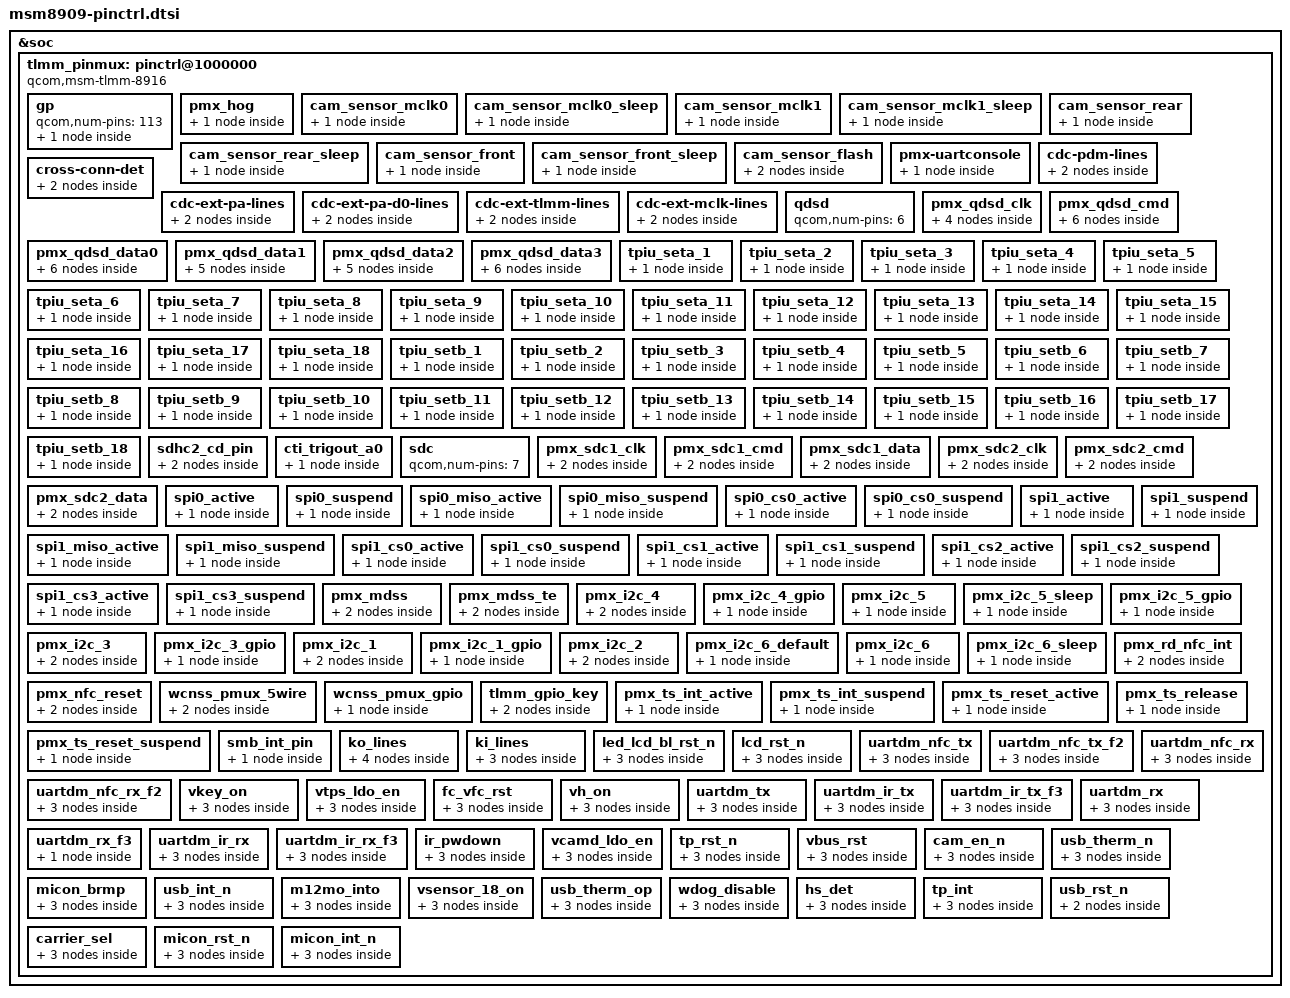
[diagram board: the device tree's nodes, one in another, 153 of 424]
/* Copyright (c) 2014-2015, The Linux Foundation. All rights reserved.
 *
 * This program is free software; you can redistribute it and/or modify
 * it under the terms of the GNU General Public License version 2 and
 * only version 2 as published by the Free Software Foundation.
 *
 * This program is distributed in the hope that it will be useful,
 * but WITHOUT ANY WARRANTY; without even the implied warranty of
 * MERCHANTABILITY or FITNESS FOR A PARTICULAR PURPOSE.  See the
 * GNU General Public License for more details.
 */
/*
 * This software is contributed or developed by KYOCERA Corporation.
 * (C) 2016 KYOCERA Corporation
 * (C) 2017 KYOCERA Corporation
 */

&soc {
	tlmm_pinmux: pinctrl@1000000 {
		compatible = "qcom,msm-tlmm-8916";
		reg = <0x1000000 0x300000>;
		interrupts = <0 208 0>;

		pinctrl-names = "default";
		pinctrl-0 = <&pmx_hog_default>;

		/*General purpose pins*/
		gp: gp {
			qcom,num-pins = <113>;
			#qcom,pin-cells = <1>;
			msm_gpio: msm_gpio {
				compatible = "qcom,msm-tlmm-gp";
				gpio-controller;
				#gpio-cells = <2>;
				interrupt-controller;
				#interrupt-cells = <2>;
				num_irqs = <113>;
			};
		};

		pmx_hog {
			qcom,pins = <&gp 1>, <&gp 9>, <&gp 10>, <&gp 11>,
					<&gp 24>, <&gp 31>, <&gp 32>, <&gp 68>,
					<&gp 69>, <&gp 71>, <&gp 72>, <&gp 73>,
					<&gp 74>, <&gp 75>, <&gp 77>, <&gp 78>,
					<&gp 79>, <&gp 80>,	<&gp 82>, <&gp 88>,
					<&gp 89>, <&gp 97>, <&gp 110>;
			qcom,num-grp-pins = <23>;
			qcom,pin-func = <0>;
			label = "hog";
			pmx_hog_default: pmx_hog_def {
				drive-strength = <2>;
				bias-pull-down;
				input-debounce = <0>;
			};
		};

		cam_sensor_mclk0 {
			/* MCLK */
			qcom,pins = <&gp 26>;
			qcom,num-grp-pins = <1>;
			qcom,pin-func = <1>;
			label = "cam-sensor-mclk0";
			 /* active state */
			cam_sensor_mclk0_default: default {
				drive-strength = <4>; /* 4 MA */
				output-low;
				bias-disable = <0>; /* No PULL */
			};
		};

		cam_sensor_mclk0_sleep {
			/* MCLK */
			qcom,pins = <&gp 26>;
			qcom,num-grp-pins = <1>;
			label = "cam-sensor-mclk0-sleep";
			/* suspend state */
			cam_sensor_mclk0_sleep: sleep {
				drive-strength = <4>; /* 4 MA */
				output-low;
				bias-disable = <0>; /* No PULL */
			};
		};

		cam_sensor_mclk1 {
			/* MCLK */
			qcom,pins = <&gp 27>;
			qcom,num-grp-pins = <1>;
			qcom,pin-func = <1>;
			label = "cam-sensor-mclk1";
			/* active state */
			cam_sensor_mclk1_default: default {
				drive-strength = <2>; /* 2 MA */
				bias-disable = <0>; /* No PULL */
			};
		};

		cam_sensor_mclk1_sleep {
			/* MCLK */
			qcom,pins = <&gp 27>;
			qcom,num-grp-pins = <1>;
			label = "cam-sensor-mclk1-sleep";
			/* suspend state */
			cam_sensor_mclk1_sleep: sleep {
				drive-strength = <2>; /* 2 MA */
				bias-pull-down; /* PULL DOWN */
			};
		};

		cam_sensor_rear {
			/* RESET */
			qcom,pins =  <&gp 35>;
			qcom,num-grp-pins = <1>;
			qcom,pin-func = <0>;
			label = "cam-sensor-rear";
			/* active state */
			cam_sensor_rear_default: default {
				drive-strength = <2>; /* 2 MA */
				output-low;
				bias-disable = <0>; /* No PULL */
			};
		};

		cam_sensor_rear_sleep {
			/* RESET */
			qcom,pins =  <&gp 35>;
			qcom,num-grp-pins = <1>;
			qcom,pin-func = <0>;
			label = "cam-sensor-rear-sleep";
			/*suspended state */
			cam_sensor_rear_sleep: sleep {
				drive-strength = <2>; /* 2 MA */
				output-low;
				bias-disable = <0>; /* No PULL */
			};
		};

		cam_sensor_front {
			/* RESET, STANDBY */
			qcom,pins = <&gp 28>, <&gp 33>;
			qcom,num-grp-pins = <2>;
			qcom,pin-func = <0>;
			label = "cam_sensor_front";
			/* active state */
			cam_sensor_front_default: default {
				drive-strength = <2>; /* 2 MA */
				bias-disable = <0>; /* No PULL */
			};
		};

		cam_sensor_front_sleep {
			/* RESET, STANDBY */
			qcom,pins = <&gp 28>, <&gp 33>;
			qcom,num-grp-pins = <2>;
			qcom,pin-func = <0>;
			label = "cam-sensor-front-sleep";
			/*suspended state */\
			cam_sensor_front_sleep: sleep {
				drive-strength = <2>; /* 2 MA */
				bias-pull-down = <0>; /* PULL DOWN */
			};
		};

		cam_sensor_flash {
			/* FLASH_RESET,FLASH_EN,FLASH_NOW */
			qcom,pins = <&gp 36>, <&gp 31>,<&gp 32> ;
			qcom,num-grp-pins = <3>;
			qcom,pin-func = <0>;
			label = "cam_sensor_flash";
			/* active state */
			cam_sensor_flash_default: default {
				drive-strength = <2>; /* 2 MA */
				bias-disable = <0>; /* No PULL */
			};
			/*suspended state */
			cam_sensor_flash_sleep: sleep {
				drive-strength = <2>; /* 2 MA */
				bias-pull-down = <0>; /* PULL DOWN */
			};
		};

		pmx-uartconsole {
			qcom,pins = <&gp 4>, <&gp 5>;
			qcom,num-grp-pins = <2>;
			qcom,pin-func = <2>;
			label = "uart-console";
			uart_console_sleep: uart-console {
				drive-strength = <2>;
				bias-pull-down;
			};
		};

		cdc-pdm-lines {
			qcom,pins = <&gp 59>, <&gp 60>, <&gp 61>,
					<&gp 62>, <&gp 63>, <&gp 64>;
			qcom,num-grp-pins = <6>;
			qcom,pin-func = <1>;
			label = "cdc-pdm-lines";
			cdc_pdm_lines_act: pdm_lines_on {
				drive-strength = <8>;
			};
			cdc_pdm_lines_sus: pdm_lines_off {
				drive-strength = <2>;
				bias-pull-down;
			};
		};

		cross-conn-det {
			qcom,pins = <&gp 97>;
			qcom,num-grp-pins = <1>;
			qcom,pin-func = <0>;
			label = "cross-conn-det-sw";
			cross_conn_det_act: lines_on {
				drive-strength = <8>;
				output-low;
				bias-pull-down;
			};
			cross_conn_det_sus: lines_off {
				drive-strength = <2>;
				bias-disable;
			};
		};

//		vdd_spkdrv {
//			qcom,pins = <&gp 4>;
//			qcom,num-grp-pins = <1>;
//			qcom,pin-func = <0>;
//			label = "vdd_spkdrv";
//			vdd_spkdrv_act: vdd_spkdrv_on {
//				drive-strength = <8>;
//				bias-pull-up;
//			};
//			vdd_spkdrv_sus: vdd_spkdrv_off {
//				drive-strength = <2>;
//				bias-disable;
//			};
//		};

		cdc-ext-pa-lines {
			qcom,pins = <&gp 94>, <&gp 96>,
					 <&gp 110>;
			qcom,num-grp-pins = <3>;
			qcom,pin-func = <1>;
			label = "cdc-ext-pa-lines";
			cdc_ext_pa_act: ext_pa_on {
				drive-strength = <8>;
			};
			cdc_ext_pa_sus: ext_pa_off {
				drive-strength = <2>;
				bias-disable;
			};
		};

		cdc-ext-pa-d0-lines {
			qcom,pins = <&gp 95>;
			qcom,num-grp-pins = <1>;
			qcom,pin-func = <2>;
			label = "cdc-ext-pa-d0-lines";
			cdc_ext_pa_d0_act: ext_pa_d0_on {
				drive-strength = <8>;
			};
			cdc_ext_pa_d0_sus: ext_pa_d0_off {
				drive-strength = <2>;
				bias-disable;
			};
		};

		cdc-ext-tlmm-lines {
			qcom,pins = <&gp 0>, <&gp 1>, <&gp 2>,
					 <&gp 3>;
			qcom,num-grp-pins = <4>;
			qcom,pin-func = <2>;
			label = "cdc-ext-tlmm-lines";
			cdc_ext_tlmm_act: ext_tlmm_on {
				drive-strength = <8>;
			};
			cdc_ext_tlmm_sus: ext_tlmm_off {
				drive-strength = <2>;
				bias-disable;
			};
		};

		cdc-ext-mclk-lines {
			qcom,pins = <&gp 98>;
			qcom,num-grp-pins = <1>;
			qcom,pin-func = <2>;
			label = "cdc-ext-mclk-lines";
			cdc_ext_mclk_act: ext_mclk_on {
				drive-strength = <8>;
			};
			cdc_ext_mclk_sus: ext_mclk_off {
				drive-strength = <2>;
				bias-disable;
			};
		};

		/* QDSD pin type */
		qdsd: qdsd {
			/* 0-> clk, 1 -> cmd, 2->data0, 3->data1, 4->data2, 5->data3 */
			qcom,num-pins = <6>;

			#qcom,pin-cells = <1>;
		};

		pmx_qdsd_clk {
			qcom,pins = <&qdsd 0>;
			qcom,num-grp-pins = <1>;
			label = "qdsd-clk";
			qdsd_clk_sdcard: clk_sdcard {
				bias-disable; /* NO pull */
				drive-strength = <7>; /* 7 MA */
			};
			qdsd_clk_trace: clk_trace {
				bias-pull-down; /* pull down */
				drive-strength = <0>; /* 0 MA */
			};
			qdsd_clk_swdtrc: clk_swdtrc {
				bias-pull-down; /* pull down */
				drive-strength = <0>; /* 0 MA */
			};
			qdsd_clk_spmi: clk_spmi {
				bias-pull-down; /* pull down */
				drive-strength = <0>; /* 0 MA */
			};
		};

		pmx_qdsd_cmd {
			qcom,pins = <&qdsd 1>;
			qcom,num-grp-pins = <1>;
			label = "qdsd-cmd";
			qdsd_cmd_sdcard: cmd_sdcard {
				bias-pull-down; /* pull down */
				drive-strength = <3>; /* 3 MA */
			};
			qdsd_cmd_trace: cmd_trace {
				bias-pull-down; /* pull down */
				drive-strength = <0>; /* 0 MA */
			};
			qdsd_cmd_swduart: cmd_uart {
				bias-pull-up; /* pull up */
				drive-strength = <0>; /* 0 MA */
			};
			qdsd_cmd_swdtrc: cmd_swdtrc {
				bias-pull-up; /* pull up */
				drive-strength = <0>; /* 0 MA */
			};
			qdsd_cmd_jtag: cmd_jtag {
				bias-disable; /* NO pull */
				drive-strength = <3>; /* 3 MA */
			};
			qdsd_cmd_spmi: cmd_spmi {
				bias-pull-down; /* pull down */
				drive-strength = <4>; /* 4 MA */
			};
		};

		pmx_qdsd_data0 {
			qcom,pins = <&qdsd 2>;
			qcom,num-grp-pins = <1>;
			label = "qdsd-data0";
			qdsd_data0_sdcard: data0_sdcard {
				bias-pull-down; /* pull down */
				drive-strength = <3>; /* 3 MA */
			};
			qdsd_data0_trace: data0_trace {
				bias-pull-down; /* pull down */
				drive-strength = <3>; /* 3 MA */
			};
			qdsd_data0_swduart: data0_uart {
				bias-pull-down; /* pull down */
				drive-strength = <0>; /* 0 MA */
			};
			qdsd_data0_swdtrc: data0_swdtrc {
				bias-pull-down; /* pull down */
				drive-strength = <0>; /* 0 MA */
			};
			qdsd_data0_jtag: data0_jtag {
				bias-pull-up; /* pull up */
				drive-strength = <0>; /* 0 MA */
			};
			qdsd_data0_spmi: data0_spmi {
				bias-pull-down; /* pull down */
				drive-strength = <0>; /* 0 MA */
			};
		};

		pmx_qdsd_data1 {
			qcom,pins = <&qdsd 3>;
			qcom,num-grp-pins = <1>;
			label = "qdsd-data1";
			qdsd_data1_sdcard: data1_sdcard {
				bias-pull-down; /* pull down */
				drive-strength = <3>; /* 3 MA */
			};
			qdsd_data1_trace: data1_trace {
				bias-pull-down; /* pull down */
				drive-strength = <3>; /* 3 MA */
			};
			qdsd_data1_swduart: data1_uart {
				bias-pull-down; /* pull down */
				drive-strength = <0>; /* 0 MA */
			};
			qdsd_data1_swdtrc: data1_swdtrc {
				bias-pull-down; /* pull down */
				drive-strength = <0>; /* 0 MA */
			};
			qdsd_data1_jtag: data1_jtag {
				bias-pull-down; /* pull down */
				drive-strength = <0>; /* 0 MA */
			};
		};

		pmx_qdsd_data2 {
			qcom,pins = <&qdsd 4>;
			qcom,num-grp-pins = <1>;
			label = "qdsd-data2";
			qdsd_data2_sdcard: data2_sdcard {
				bias-pull-down; /* pull down */
				drive-strength = <3>; /* 3 MA */
			};
			qdsd_data2_trace: data2_trace {
				bias-pull-down; /* pull down */
				drive-strength = <3>; /* 3 MA */
			};
			qdsd_data2_swduart: data2_uart {
				bias-pull-down; /* pull down */
				drive-strength = <0>; /* 0 MA */
			};
			qdsd_data2_swdtrc: data2_swdtrc {
				bias-pull-down; /* pull down */
				drive-strength = <0>; /* 0 MA */
			};
			qdsd_data2_jtag: data2_jtag {
				bias-pull-up; /* pull up */
				drive-strength = <3>; /* 3 MA */
			};
		};

		pmx_qdsd_data3 {
			qcom,pins = <&qdsd 5>;
			qcom,num-grp-pins = <1>;
			label = "qdsd-data3";
			qdsd_data3_sdcard: data3_sdcard {
				bias-pull-down; /* pull down */
				drive-strength = <3>; /* 3 MA */
			};
			qdsd_data3_trace: data3_trace {
				bias-pull-down; /* pull down */
				drive-strength = <3>; /* 3 MA */
			};
			qdsd_data3_swduart: data3_uart {
				bias-pull-up; /* pull up */
				drive-strength = <0>; /* 0 MA */
			};
			qdsd_data3_swdtrc: data3_swdtrc {
				bias-pull-up; /* pull up */
				drive-strength = <0>; /* 0 MA */
			};
			qdsd_data3_jtag: data3_jtag {
				bias-pull-up; /* pull up */
				drive-strength = <0>; /* 0 MA */
			};
			qdsd_data3_spmi: data3_spmi {
				bias-pull-down; /* pull down */
				drive-strength = <3>; /* 3 MA */
			};
		};

		/* CoreSight */
		tpiu_seta_1 {
			qcom,pins = <&gp 6>;
			qcom,num-grp-pins = <1>;
			qcom,pin-func = <11>;
			label = "tpiu-seta-1";
			seta_1: seta {
				drive-strength = <16>;
				bias-disable;
			};
		};


		tpiu_seta_2 {
			qcom,pins = <&gp 8>;
			qcom,num-grp-pins = <1>;
			qcom,pin-func = <8>;
			label = "tpiu-seta-2";
			seta_2: seta {
				drive-strength = <16>;
				bias-disable;
			};
		};

		tpiu_seta_3 {
			qcom,pins = <&gp 9>;
			qcom,num-grp-pins = <1>;
			qcom,pin-func = <7>;
			label = "tpiu-seta-3";
			seta_3: seta {
				drive-strength = <16>;
				bias-disable;
			};
		};

		tpiu_seta_4 {
			qcom,pins = <&gp 10>;
			qcom,num-grp-pins = <1>;
			qcom,pin-func = <4>;
			label = "tpiu-seta-4";
			seta_4: seta {
				drive-strength = <16>;
				bias-disable;
			};
		};

		tpiu_seta_5 {
			qcom,pins = <&gp 39>;
			qcom,num-grp-pins = <1>;
			qcom,pin-func = <2>;
			label = "tpiu-seta-5";
			seta_5: seta {
				drive-strength = <16>;
				bias-disable;
			};
		};

		tpiu_seta_6 {
			qcom,pins = <&gp 40>;
			qcom,num-grp-pins = <1>;
			qcom,pin-func = <2>;
			label = "tpiu-seta-6";
			seta_6: seta {
				drive-strength = <16>;
				bias-disable;
			};
		};

		tpiu_seta_7 {
			qcom,pins = <&gp 41>;
			qcom,num-grp-pins = <1>;
			qcom,pin-func = <2>;
			label = "tpiu-seta-7";
			seta_7: seta {
				drive-strength = <16>;
				bias-disable;
			};
		};

		tpiu_seta_8 {
			qcom,pins = <&gp 42>;
			qcom,num-grp-pins = <1>;
			qcom,pin-func = <2>;
			label = "tpiu-seta-8";
			seta_8: seta {
				drive-strength = <16>;
				bias-disable;
			};
		};

		tpiu_seta_9 {
			qcom,pins = <&gp 43>;
			qcom,num-grp-pins = <1>;
			qcom,pin-func = <3>;
			label = "tpiu-seta-9";
			seta_9: seta {
				drive-strength = <16>;
				bias-disable;
			};
		};

		tpiu_seta_10 {
			qcom,pins = <&gp 45>;
			qcom,num-grp-pins = <1>;
			qcom,pin-func = <3>;
			label = "tpiu-seta-10";
			seta_10: seta {
				drive-strength = <16>;
				bias-disable;
			};
		};

		tpiu_seta_11 {
			qcom,pins = <&gp 46>;
			qcom,num-grp-pins = <1>;
			qcom,pin-func = <2>;
			label = "tpiu-seta-11";
			seta_11: seta {
				drive-strength = <16>;
				bias-disable;
			};
		};

		tpiu_seta_12 {
			qcom,pins = <&gp 47>;
			qcom,num-grp-pins = <1>;
			qcom,pin-func = <2>;
			label = "tpiu-seta-12";
			seta_12: seta {
				drive-strength = <16>;
				bias-disable;
			};
		};

		tpiu_seta_13 {
			qcom,pins = <&gp 48>;
			qcom,num-grp-pins = <1>;
			qcom,pin-func = <2>;
			label = "tpiu-seta-13";
			seta_13: seta {
				drive-strength = <16>;
				bias-disable;
			};
		};

		tpiu_seta_14 {
			qcom,pins = <&gp 58>;
			qcom,num-grp-pins = <1>;
			qcom,pin-func = <1>;
			label = "tpiu-seta-14";
			seta_14: seta {
				drive-strength = <16>;
				bias-disable;
			};
		};

		tpiu_seta_15 {
			qcom,pins = <&gp 65>;
			qcom,num-grp-pins = <1>;
			qcom,pin-func = <3>;
			label = "tpiu-seta-15";
			seta_15: seta {
				drive-strength = <16>;
				bias-disable;
			};
		};

		tpiu_seta_16 {
			qcom,pins = <&gp 94>;
			qcom,num-grp-pins = <1>;
			qcom,pin-func = <3>;
			label = "tpiu-seta-16";
			seta_16: seta {
				drive-strength = <16>;
				bias-disable;
			};
		};

		tpiu_seta_17 {
			qcom,pins = <&gp 96>;
			qcom,num-grp-pins = <1>;
			qcom,pin-func = <4>;
			label = "tpiu-seta-17";
			seta_17: seta {
				drive-strength = <16>;
				bias-disable;
			};
		};

		tpiu_seta_18 {
			qcom,pins = <&gp 97>;
			qcom,num-grp-pins = <1>;
			qcom,pin-func = <2>;
			label = "tpiu-seta-18";
			seta_18: seta {
				drive-strength = <16>;
				bias-disable;
			};
		};

		tpiu_setb_1 {
			qcom,pins = <&gp 4>;
			qcom,num-grp-pins = <1>;
			qcom,pin-func = <13>;
			label = "tpiu-setb-1";
			setb_1: setb {
				drive-strength = <16>;
				bias-disable;
			};
		};

		tpiu_setb_2 {
			qcom,pins = <&gp 5>;
			qcom,num-grp-pins = <1>;
			qcom,pin-func = <13>;
			label = "tpiu-setb-2";
			setb_2: setb {
				drive-strength = <16>;
				bias-disable;
			};
		};

		tpiu_setb_3 {
			qcom,pins = <&gp 14>;
			qcom,num-grp-pins = <1>;
			qcom,pin-func = <9>;
			label = "tpiu-setb-3";
			setb_3: setb {
				drive-strength = <16>;
				bias-disable;
			};
		};

		tpiu_setb_4 {
			qcom,pins = <&gp 16>;
			qcom,num-grp-pins = <1>;
			qcom,pin-func = <7>;
			label = "tpiu-setb-4";
			setb_4: setb {
				drive-strength = <16>;
				bias-disable;
			};
		};

		tpiu_setb_5 {
			qcom,pins = <&gp 17>;
			qcom,num-grp-pins = <1>;
			qcom,pin-func = <8>;
			label = "tpiu-setb-5";
			setb_5: setb {
				drive-strength = <16>;
				bias-disable;
			};
		};

		tpiu_setb_6 {
			qcom,pins = <&gp 26>;
			qcom,num-grp-pins = <1>;
			qcom,pin-func = <10>;
			label = "tpiu-setb-6";
			setb_6: setb {
				drive-strength = <16>;
				bias-disable;
			};
		};

		tpiu_setb_7 {
			qcom,pins = <&gp 27>;
			qcom,num-grp-pins = <1>;
			qcom,pin-func = <10>;
			label = "tpiu-setb-7";
			setb_7: setb {
				drive-strength = <16>;
				bias-disable;
			};
		};

		tpiu_setb_8 {
			qcom,pins = <&gp 28>;
			qcom,num-grp-pins = <1>;
			qcom,pin-func = <10>;
			label = "tpiu-setb-8";
			setb_8: setb {
				drive-strength = <16>;
				bias-disable;
			};
		};

		tpiu_setb_9 {
			qcom,pins = <&gp 29>;
			qcom,num-grp-pins = <1>;
			qcom,pin-func = <7>;
			label = "tpiu-setb-9";
			setb_9: setb {
				drive-strength = <16>;
				bias-disable;
			};
		};

		tpiu_setb_10 {
			qcom,pins = <&gp 30>;
			qcom,num-grp-pins = <1>;
			qcom,pin-func = <7>;
			label = "tpiu-setb-10";
			setb_10: setb {
				drive-strength = <16>;
				bias-disable;
			};
		};

		tpiu_setb_11 {
			qcom,pins = <&gp 31>;
			qcom,num-grp-pins = <1>;
			qcom,pin-func = <8>;
			label = "tpiu-setb-11";
			setb_11: setb {
				drive-strength = <16>;
				bias-disable;
			};
		};

		tpiu_setb_12 {
			qcom,pins = <&gp 32>;
			qcom,num-grp-pins = <1>;
			qcom,pin-func = <3>;
			label = "tpiu-setb-12";
			setb_12: setb {
				drive-strength = <16>;
				bias-disable;
			};
		};

		tpiu_setb_13 {
			qcom,pins = <&gp 33>;
			qcom,num-grp-pins = <1>;
			qcom,pin-func = <2>;
			label = "tpiu-setb-13";
			setb_13: setb {
				drive-strength = <16>;
				bias-disable;
			};
		};

		tpiu_setb_14 {
			qcom,pins = <&gp 34>;
			qcom,num-grp-pins = <1>;
			qcom,pin-func = <2>;
			label = "tpiu-setb-14";
			setb_14: setb {
				drive-strength = <16>;
				bias-disable;
			};
		};

		tpiu_setb_15 {
			qcom,pins = <&gp 35>;
			qcom,num-grp-pins = <1>;
			qcom,pin-func = <2>;
			label = "tpiu-setb-15";
			setb_15: setb {
				drive-strength = <16>;
				bias-disable;
			};
		};

		tpiu_setb_16 {
			qcom,pins = <&gp 36>;
			qcom,num-grp-pins = <1>;
			qcom,pin-func = <1>;
			label = "tpiu-setb-16";
			setb_16: setb {
				drive-strength = <16>;
				bias-disable;
			};
		};

		tpiu_setb_17 {
			qcom,pins = <&gp 37>;
			qcom,num-grp-pins = <1>;
			qcom,pin-func = <2>;
			label = "tpiu-setb-17";
			setb_17: setb {
				drive-strength = <16>;
				bias-disable;
			};
		};

		tpiu_setb_18 {
			qcom,pins = <&gp 93>;
			qcom,num-grp-pins = <1>;
			qcom,pin-func = <1>;
			label = "tpiu-setb-18";
			setb_18: setb {
				drive-strength = <16>;
				bias-disable;
			};
		};

		sdhc2_cd_pin {
			qcom,pins = <&gp 38>;
			qcom,num-grp-pins = <1>;
			qcom,pin-func = <0>;
			label = "cd-gpio";
			sdc2_cd_on: cd_on {
				drive-strength = <2>;
				bias-pull-up;
			};
			sdc2_cd_off: cd_off {
				drive-strength = <2>;
				bias-disable;
			};
		};

		cti_trigout_a0 {
			qcom,pins = <&gp 23>;
			qcom,num-grp-pins = <1>;
			qcom,pin-func = <2>;
			label = "cti-trigout-a0";
			trigout_a0: trigout_a0 {
				drive-strength = <2>;
				bias-disable;
			};
		};

		/* SDC pin type */
		sdc: sdc {
			/* 0-2 for sdc1 4-6 for sdc2 */
			qcom,num-pins = <7>;
			/* Order of pins */
			/* SDC1: CLK -> 0, CMD -> 1, DATA -> 2 */
			/* SDC2: CLK -> 4, CMD -> 5, DATA -> 6 */
			#qcom,pin-cells = <1>;
		};

		pmx_sdc1_clk {
			qcom,pins = <&sdc 0>;
			qcom,num-grp-pins = <1>;
			label = "sdc1-clk";
			sdc1_clk_on: clk_on {
				bias-disable; /* NO pull */
				drive-strength = <16>; /* 16 MA */
			};
			sdc1_clk_off: clk_off {
				bias-disable; /* NO pull */
				drive-strength = <2>; /* 2 MA */
			};
		};

		pmx_sdc1_cmd {
			qcom,pins = <&sdc 1>;
			qcom,num-grp-pins = <1>;
			label = "sdc1-cmd";
			sdc1_cmd_on: cmd_on {
				bias-disable; /* NO pull */
				drive-strength = <8>; /* 8 MA */
			};
			sdc1_cmd_off: cmd_off {
				bias-pull-up; /* pull up */
				drive-strength = <2>; /* 2 MA */
			};
		};

		pmx_sdc1_data {
			qcom,pins = <&sdc 2>;
			qcom,num-grp-pins = <1>;
			label = "sdc1-data";
			sdc1_data_on: data_on {
				bias-pull-up; /* pull up */
				drive-strength = <8>; /* 8 MA */
			};
			sdc1_data_off: data_off {
				bias-pull-up; /* pull up */
				drive-strength = <2>; /* 2 MA */
			};
		};

		pmx_sdc2_clk {
			qcom,pins = <&sdc 4>;
			qcom,num-grp-pins = <1>;
			label = "sdc2-clk";
			sdc2_clk_on: clk_on {
				bias-disable; /* NO pull */
				drive-strength = <12>; /* 12 MA */
			};
			sdc2_clk_off: clk_off {
				bias-pull-down; /* pull down */
				drive-strength = <2>; /* 2 MA */
			};
		};

		pmx_sdc2_cmd {
			qcom,pins = <&sdc 5>;
			qcom,num-grp-pins = <1>;
			label = "sdc2-cmd";
			sdc2_cmd_on: cmd_on {
				bias-pull-up; /* pull up */
				drive-strength = <8>; /* 8 MA */
			};
			sdc2_cmd_off: cmd_off {
				bias-pull-down; /* pull down */
				drive-strength = <2>; /* 2 MA */
			};
		};

		pmx_sdc2_data {
			qcom,pins = <&sdc 6>;
			qcom,num-grp-pins = <1>;
			label = "sdc2-data";
			sdc2_data_on: data_on {
				bias-pull-up; /* pull up */
				drive-strength = <8>; /* 8 MA */
			};
			sdc2_data_off: data_off {
				bias-pull-down; /* pull down */
				drive-strength = <2>; /* 2 MA */
			};
		};
		spi0_active {
                        /* MOSI, CLK */
                        qcom,pins = <&gp 8>, <&gp 11>;
                        qcom,num-grp-pins = <2>;
                        qcom,pin-func = <1>;
                        label = "spi0-active";
                        /* active state */
                        spi0_default: spi0_default {
                                drive-strength = <2>; /* 2 MA */
                                output-low;
                                bias-disable = <0>;
                        };
                };

                spi0_suspend {
                        /* MOSI, CLK */
                        qcom,pins = <&gp 8>, <&gp 11>;
                        qcom,num-grp-pins = <2>;
                        qcom,pin-func = <0>;
                        label = "spi0-suspend";
                        /* suspended state */
                        spi0_sleep: spi0_sleep {
                                drive-strength = <2>; /* 2 MA */
                                output-low;
                                bias-disable = <0>;
                        };
                };

		spi0_miso_active {
                        /* MISO */
                        qcom,pins = <&gp 9>;
                        qcom,num-grp-pins = <1>;
                        qcom,pin-func = <1>;
                        label = "spi0-miso-active";
                        /* active state */
                        spi0_miso_default: spi0_miso_default {
                                drive-strength = <2>; /* 2 MA */
				input-debounce = <0>;
                                bias-pull-down;
                        };
                };
                spi0_miso_suspend {
                        /* MISO */
                        qcom,pins = <&gp 9>;
                        qcom,num-grp-pins = <1>;
                        qcom,pin-func = <0>;
                        label = "spi0-miso-suspend";
                        /* suspended state */
                        spi0_miso_sleep: spi0_miso_sleep {
                                drive-strength = <2>; /* 2 MA */
				input-debounce = <0>;
                                bias-pull-down;
                        };
                };

                spi0_cs0_active {
                        /* CS */
                        qcom,pins = <&gp 10>;
                        qcom,num-grp-pins = <1>;
                        qcom,pin-func = <1>;
                        label = "spi0-cs0-active";
                        spi0_cs0_active: cs0_active {
                                drive-strength = <2>;
                                bias-disable = <0>;
                        };
                };


                spi0_cs0_suspend {
                        /* CS */
                        qcom,pins = <&gp 10>;
                        qcom,num-grp-pins = <1>;
                        qcom,pin-func = <0>;
                        label = "spi0-cs0-suspend";
                        spi0_cs0_sleep: cs0_sleep {
                                drive-strength = <2>;
                                output-high;
                                bias-disable = <0>;
                        };
                };

		spi1_active {
                        /* MOSI, CLK */
                        qcom,pins = <&gp 4>, <&gp 7>;
                        qcom,num-grp-pins = <2>;
                        qcom,pin-func = <1>;
                        label = "spi1-active";
                        /* active state */
                        spi1_default: spi1_default {
                                drive-strength = <4>; /* 4 MA */
                                bias-disable = <0>;
                        };
                };

                spi1_suspend {
                        /* MOSI, CLK */
                        qcom,pins = <&gp 4>, <&gp 7>;
                        qcom,num-grp-pins = <2>;
                        qcom,pin-func = <0>;
                        label = "spi1-suspend";
                        /* suspended state */
                        spi1_sleep: spi1_sleep {
                                drive-strength = <4>; /* 4 MA */
                                output-low;
                                bias-disable = <0>;
                        };
                };

		spi1_miso_active {
                        /* MISO */
                        qcom,pins = <&gp 5>;
                        qcom,num-grp-pins = <1>;
                        qcom,pin-func = <1>;
                        label = "spi1-miso-active";
                        /* active state */
                        spi1_miso_default: spi1_miso_default {
                                drive-strength = <2>; /* 2 MA */
                                input-debounce = <0>;
                                bias-disable = <0>;
                        };
                };
                spi1_miso_suspend {
                        /* MISO */
                        qcom,pins = <&gp 5>;
                        qcom,num-grp-pins = <1>;
                        qcom,pin-func = <0>;
                        label = "spi1-miso-suspend";
                        /* suspended state */
                        spi1_miso_sleep: spi1_miso_sleep {
                                drive-strength = <2>; /* 2 MA */
                                input-debounce = <0>;
                                bias-pull-down;
                        };
                };

                spi1_cs0_active {
                        /* CS */
                        qcom,pins = <&gp 6>;
                        qcom,num-grp-pins = <1>;
                        qcom,pin-func = <1>;
                        label = "spi1-cs0-active";
                        spi1_cs0_active: cs0_active {
                                drive-strength = <2>;
                                bias-disable = <0>;
                        };
                };


                spi1_cs0_suspend {
                        /* CS */
                        qcom,pins = <&gp 6>;
                        qcom,num-grp-pins = <1>;
                        qcom,pin-func = <0>;
                        label = "spi1-cs0-suspend";
                        spi1_cs0_sleep: cs0_sleep {
                                drive-strength = <2>;
                                output-low;
                                bias-disable = <0>;
                        };
                };

                spi1_cs1_active {
                        /* CS */
                        qcom,pins = <&gp 97>;
                        qcom,num-grp-pins = <1>;
                        qcom,pin-func = <1>;
                        label = "spi1-cs1-active";
                        spi1_cs1_active: cs1_active {
                                drive-strength = <2>;
                                bias-disable = <0>;
                        };
                };


                spi1_cs1_suspend {
                        /* CS */
                        qcom,pins = <&gp 97>;
                        qcom,num-grp-pins = <1>;
                        qcom,pin-func = <0>;
                        label = "spi1-cs1-suspend";
                        spi1_cs1_sleep: cs1_sleep {
                                drive-strength = <2>;
                                output-low;
                                bias-disable = <0>;
                        };
                };

                spi1_cs2_active {
                        /* CS */
                        qcom,pins = <&gp 37>;
                        qcom,num-grp-pins = <1>;
                        qcom,pin-func = <1>;
                        label = "spi1-cs2-active";
                        spi1_cs2_active: cs2_active {
                                drive-strength = <4>;
                                bias-disable = <0>;
                        };
                };


                spi1_cs2_suspend {
                        /* CS */
                        qcom,pins = <&gp 37>;
                        qcom,num-grp-pins = <1>;
                        qcom,pin-func = <0>;
                        label = "spi1-cs2-suspend";
                        spi1_cs2_sleep: cs2_sleep {
                                drive-strength = <4>;
                                output-high;
                                bias-disable = <0>;
                        };
                };

                spi1_cs3_active {
                        /* CS */
                        qcom,pins = <&gp 65>;
                        qcom,num-grp-pins = <1>;
                        qcom,pin-func = <2>;
                        label = "spi1-cs3-active";
                        spi1_cs3_active: cs3_active {
                                drive-strength = <2>;
                                bias-disable = <0>;
                        };
                };


                spi1_cs3_suspend {
                        /* CS */
                        qcom,pins = <&gp 65>;
                        qcom,num-grp-pins = <1>;
                        qcom,pin-func = <0>;
                        label = "spi1-cs3-suspend";
                        spi1_cs3_sleep: cs3_sleep {
                                drive-strength = <2>;
                                output-low;
                                bias-disable = <0>;
                        };
                };

		pmx_mdss: pmx_mdss {
			label = "mdss-pins";
			qcom,pin-func = <0>;

			mdss_dsi_active: active {
				drive-strength = <8>; /* 8 mA */
				bias-disable = <0>; /* no pull */
				output-high;
			};
			mdss_dsi_suspend: suspend {
				drive-strength = <2>; /* 2 mA */
				bias-pull-down; /* pull down */
				output-low;
			};
		};

		pmx_mdss_te: pmx_mdss_te {
			label = "mdss-te-pin";
			qcom,pin-func = <1>;
			mdss_te_active: active {
				drive-strength = <2>; /* 2 mA */
				bias-pull-down; /* pull down */
				input-debounce = <0>;
			};
			mdss_te_suspend: suspend {
				drive-strength = <2>; /* 2 mA */
				bias-pull-down; /* pull down */
				input-debounce = <0>;
			};
		};

		pmx_i2c_4 {
			qcom,pins = <&gp 14>, <&gp 15>; /* SDA, SCL */
			qcom,num-grp-pins = <2>;
			qcom,pin-func = <2>;
			label = "pmx_i2c_4";

			i2c_4_active: i2c_4_active {
				drive-strength = <2>;
				bias-disable;
			};

			i2c_4_sleep: i2c_4_sleep {
				drive-strength = <2>;
				bias-disable;
			};
		};

		pmx_i2c_4_gpio {
			/* CLK, DATA */
			qcom,pins = <&gp 14>, <&gp 15>;
			qcom,num-grp-pins = <2>;
			qcom,pin-func = <0>;
			label = "pmx_i2c_4_gpio";

			i2c_4_gpio: i2c_4_gpio {
				drive-strength = <2>; /* 2 MA */
				bias-disable;         /* No PULL */
				input-debounce = <0>;
			};
		};

		pmx_i2c_5 {
                        /* CLK, DATA */
                        qcom,pins = <&gp 19>, <&gp 18>;
                        qcom,num-grp-pins = <2>;
                        qcom,pin-func = <2>;
                        label = "pmx_i2c_5";

                        i2c_5_active: i2c_5_active {
                                drive-strength = <2>; /* 2 MA */
                                bias-disable = <0>; /* No PULL */
                        };
                };

		pmx_i2c_5_sleep {
                        /* CLK, DATA */
                        qcom,pins = <&gp 19>, <&gp 18>;
                        qcom,num-grp-pins = <2>;
                        qcom,pin-func = <2>;
                        label = "pmx_i2c_5_sleep";

                        i2c_5_sleep: i2c_5_sleep {
                                drive-strength = <2>; /* 2 MA */
                                bias-disable = <0>; /* No PULL */
                        };
                };

		pmx_i2c_5_gpio {
			/* CLK, DATA */
			qcom,pins = <&gp 19>, <&gp 18>;
			qcom,num-grp-pins = <2>;
			qcom,pin-func = <0>;
			label = "pmx_i2c_5_gpio";

			i2c_5_gpio: i2c_5_gpio {
				drive-strength = <2>; /* 2 MA */
				bias-disable;         /* No PULL */
				input-debounce = <0>;
			};
		};

		pmx_i2c_3 {
                        /* CLK, DATA */
			qcom,pins = <&gp 29>, <&gp 30>;
			qcom,num-grp-pins = <2>;
			qcom,pin-func = <1>;
			label = "pmx_i2c_3";

			i2c_3_active: i2c_3_active {
				drive-strength = <2>; /* 2 MA */
				bias-disable = <0>; /* No PULL */
			};

			i2c_3_sleep: i2c_3_sleep {
				drive-strength = <2>; /* 2 MA */
				bias-disable = <0>; /* No PULL */
			};
		};

		pmx_i2c_3_gpio {
			/* CLK, DATA */
			qcom,pins = <&gp 29>, <&gp 30>;
			qcom,num-grp-pins = <2>;
			qcom,pin-func = <0>;
			label = "pmx_i2c_3_gpio";

			i2c_3_gpio: i2c_3_gpio {
				drive-strength = <2>; /* 2 MA */
				bias-disable;         /* No PULL */
				input-debounce = <0>;
			};
		};

		pmx_i2c_1 {
                        /* CLK, DATA */
			qcom,pins = <&gp 6>, <&gp 7>;
			qcom,num-grp-pins = <2>;
			qcom,pin-func = <3>;
			label = "pmx_i2c_1";

			i2c_1_active: i2c_1_active {
				drive-strength = <2>; /* 2 MA */
				bias-disable = <0>; /* No PULL */
			};

			i2c_1_sleep: i2c_1_sleep {
				drive-strength = <2>; /* 2 MA */
				bias-disable = <0>; /* No PULL */
			};
		};

		pmx_i2c_1_gpio {
			/* CLK, DATA */
			qcom,pins = <&gp 6>, <&gp 7>;
			qcom,num-grp-pins = <2>;
			qcom,pin-func = <0>;
			label = "pmx_i2c_1_gpio";

			i2c_1_gpio: i2c_1_gpio {
				drive-strength = <2>; /* 2 MA */
				bias-disable;         /* No PULL */
				input-debounce = <0>;
			};
		};

		pmx_i2c_2 {
			/* CLK, DATA */
			qcom,pins = <&gp 111>, <&gp 112>;
			qcom,num-grp-pins = <2>;
			qcom,pin-func = <3>;
			label = "pmx_i2c_2";
			/* active state */
			i2c_2_active: i2c_2_active{
				drive-strength = <2>; /* 2 MA */
				bias-disable; /* No PULL */
			};
			/* suspended state */
				i2c_2_sleep: i2c_2_sleep {
				drive-strength = <2>; /* 2 MA */
				bias-disable; /* No PULL */
			};
		};

		pmx_i2c_6_default {
			/* CLK, DATA */
			qcom,pins = <&gp 10>, <&gp 11>;
			qcom,num-grp-pins = <2>;
			qcom,pin-func = <0>;
			label = "pmx_i2c_6_default";
				i2c_6_default: i2c_6_default {
				drive-strength = <2>; /* 2 MA */
				bias-pull-down;
			};
		};

		pmx_i2c_6 {
			/* CLK, DATA */
			qcom,pins = <&gp 10>, <&gp 11>;
			qcom,num-grp-pins = <2>;
			qcom,pin-func = <2>;
			label = "pmx_i2c_6";
			/* active state */
			i2c_6_active: i2c_6_active{
				drive-strength = <2>; /* 2 MA */
				bias-disable; /* No PULL */
			};
		};

		pmx_i2c_6_sleep {
			/* CLK, DATA */
			qcom,pins = <&gp 10>, <&gp 11>;
			qcom,num-grp-pins = <2>;
			qcom,pin-func = <0>;
			label = "pmx_i2c_6_sleep";
			/* suspended state */
				i2c_6_sleep: i2c_6_sleep {
				drive-strength = <2>; /* 2 MA */
				bias-pull-down;
			};
		};

		pmx_rd_nfc_int{
			qcom,pins = <&gp 21>;
			qcom,pin-func = <0>;
			qcom,num-grp-pins = <1>;
			label = "pmx_nfc_int";

			nfc_int_active: active {
				drive-strength = <6>;
				bias-pull-up;
			};

			nfc_int_suspend: suspend {
				drive-strength = <6>;
				bias-pull-up;
			};
		};

		pmx_nfc_reset{
			qcom,pins = <&gp 20>;
			qcom,pin-func = <0>;
			qcom,num-grp-pins = <1>;
			label = "pmx_nfc_disable";

			nfc_disable_active: active {
				drive-strength = <6>;
				bias-pull-up;
			};

			nfc_disable_suspend: suspend {
				drive-strength = <6>;
				bias-disable;
			};
		};

		wcnss_pmux_5wire: wcnss_pmux_5wire {
			/* Uses general purpose pins */
			qcom,pins = <&gp 40>, <&gp 41>,
				    <&gp 42>, <&gp 43>,
				    <&gp 44>;
			qcom,num-grp-pins = <5>;
			qcom,pin-func = <1>;
			label = "wcnss_5wire_pins";
			/* Active configuration of bus pins */
			wcnss_default: wcnss_default {
			        drive-strength = <6>; /* 6 MA */
			        bias-pull-up; /* PULL UP */
			};
			wcnss_sleep: wcnss_sleep {
			        drive-strength = <2>; /* 2 MA */
			        bias-pull-down; /* PULL Down */
			};
		};

		wcnss_pmux_gpio: wcnss_pmux_gpio {
			/* Uses general purpose pins */
			qcom,pins = <&gp 40>, <&gp 41>,
				    <&gp 42>, <&gp 43>,
				    <&gp 44>;
			qcom,num-grp-pins = <5>;
			qcom,pin-func = <0>;
			label = "wcnss_5gpio_pins";
			/* Active configuration of bus pins */
			wcnss_gpio_default: wcnss_gpio_default {
			        drive-strength = <6>; /* 6 MA */
			        bias-pull-up; /* PULL UP */
			};
		};

		tlmm_gpio_key {
			qcom,pins = <&gp 25>;
			qcom,pin-func = <0>;
			qcom,num-grp-pins = <1>;
			label = "tlmm_gpio_key";
			gpio_key_active: gpio_key_active {
				drive-strength = <2>;
				input-debounce = <0>;
				bias-pull-up;
			};
			gpio_key_suspend: gpio_key_suspend {
				drive-strength = <2>;
				input-debounce = <0>;
				bias-pull-up;
			};
		};

		/* add pingrp for touchscreen */
		pmx_ts_int_active {
			qcom,pins = <&gp 50>;
			qcom,pin-func = <0>;
			qcom,num-grp-pins = <1>;
			label = "pmx_ts_int_active";

			ts_int_active: ts_int_active {
				drive-strength = <2>;
				bias-pull-down;
			};
		};

		pmx_ts_int_suspend {
			qcom,pins = <&gp 50>;
			qcom,pin-func = <0>;
			qcom,num-grp-pins = <1>;
			label = "pmx_ts_int_suspend";

			ts_int_suspend: ts_int_suspend {
				drive-strength = <2>;
				bias-pull-down;
			};
		};

		pmx_ts_reset_active {
			qcom,pins = <&gp 65>;
			qcom,pin-func = <0>;
			qcom,num-grp-pins = <1>;
			label = "pmx_ts_reset_active";

			ts_reset_active: ts_reset_active {
				drive-strength = <2>;
				bias-disable;
			};
		};

		pmx_ts_reset_suspend {
			qcom,pins = <&gp 65>;
			qcom,pin-func = <0>;
			qcom,num-grp-pins = <1>;
			label = "pmx_ts_reset_suspend";

			ts_reset_suspend: ts_reset_suspend {
				drive-strength = <2>;
				bias-disable;
			};
		};

		pmx_ts_release {
			qcom,pins = <&gp 50>, <&gp 65>;
			qcom,num-grp-pins = <2>;
			label = "pmx_ts_release";

			ts_release: ts_release {
				drive-strength = <2>;
				bias-pull-down;
			};
		};

		smb_int_pin {
			qcom,pins = <&gp 58>;
			qcom,num-grp-pins = <1>;
			qcom,pin-func = <0>;
			label = "smb1360_int_gpio";
			smb_int_default: smb_int_default {
				drive-strength = <2>;	/* 2 MA */
				input-debounce = <0>;
				bias-disable;
			};
		};

		ko_lines {
			qcom,pins = <&gp 3>, <&gp 16>, <&gp 17>, <&gp 28>,
					<&gp 33>, <&gp 34>, <&gp 50>, <&gp 57>,
					<&gp 65>, <&gp 92>;
			qcom,pin-func = <0>;
			qcom,num-grp-pins = <10>;
			label = "ko";
			ko_default: ko_default {
				drive-strength = <2>;
				output-low;
				bias-disable;
			};
			ko_active: ko_active {
				drive-strength = <2>;
				output-low;
				bias-disable;
			};
			ko_suspend: ko_suspend {
				drive-strength = <2>;
				output-low;
				bias-pull-down;
			};
			ko_prescan: ko_prescan {
				drive-strength = <2>;
                input-enable;
				bias-pull-up;
			};
		};
		ki_lines {
			qcom,pins = <&gp 90>, <&gp 91>, <&gp 94>,
					<&gp 95>, <&gp 96>, <&gp 98>;
			qcom,pin-func = <0>;
			qcom,num-grp-pins = <6>;
			label = "ki";
			ki_default: ki_default {
				drive-strength = <2>;
				input-debounce = <0>;
				bias-pull-up;
			};
			ki_active: ki_active {
				drive-strength = <2>;
				input-debounce = <0>;
				bias-pull-up;
			};
			ki_suspend: ki_suspend {
				drive-strength = <2>;
				input-debounce = <0>;
				bias-pull-up;
			};
		};

		led_lcd_bl_rst_n {
			qcom,pins = <&gp 0>;
			qcom,pin-func = <0>;
			qcom,num-grp-pins = <1>;
			label = "led_lcd_bl_rst_n";
			led_lcd_bl_rst_n_default: led_lcd_bl_rst_n_default {
				drive-strength = <2>;
				output-low;
				bias-disable;
			};
			led_lcd_bl_rst_n_active: led_lcd_bl_rst_n_active {
				drive-strength = <2>;
				output-low;
				bias-disable;
			};
			led_lcd_bl_rst_n_suspend: led_lcd_bl_rst_n_suspend {
				drive-strength = <2>;
				output-high;
				bias-disable;
			};
		};

		lcd_rst_n {
			qcom,pins = <&gp 2>;
			qcom,pin-func = <0>;
			qcom,num-grp-pins = <1>;
			label = "lcd_rst_n";
			lcd_rst_n_default: lcd_rst_n_default {
				drive-strength = <2>;
				output-low;
				bias-disable;
			};
			lcd_rst_n_active: lcd_rst_n_active {
				drive-strength = <2>;
				output-low;
				bias-disable;
			};
			lcd_rst_n_suspend: lcd_rst_n_suspend {
				drive-strength = <2>;
				output-low;
				bias-disable;
			};
		};

		uartdm_nfc_tx {
			qcom,pins = <&gp 4>;
			qcom,pin-func = <0>;
			qcom,num-grp-pins = <1>;
			label = "uartdm_nfc_tx";
			uartdm_nfc_tx_default: uartdm_nfc_tx_default {
				drive-strength = <2>;
				output-high;
				bias-pull-up;
			};
			uartdm_nfc_tx_active: uartdm_nfc_tx_active {
				drive-strength = <2>;
				output-high;
				bias-pull-up;
			};
			uartdm_nfc_tx_suspend: uartdm_nfc_tx_suspend {
				drive-strength = <2>;
				output-high;
				bias-pull-up;
			};
		};

		uartdm_nfc_tx_f2 {
			qcom,pins = <&gp 4>;
			qcom,pin-func  = <2>;
			qcom,num-grp-pins = <1>;
			label = "uartdm_nfc_tx_f2";
			uartdm_nfc_tx_f2_default: uartdm_nfc_tx_f2_default {
				drive-strength = <2>;
				output-high;
				bias-pull-up;
			};
			uartdm_nfc_tx_f2_active: uartdm_nfc_tx_f2_active {
				drive-strength = <2>;
				output-high;
				bias-pull-up;
			};
			uartdm_nfc_tx_f2_suspend: uartdm_nfc_tx_f2_suspend {
				drive-strength = <2>;
				output-high;
				bias-pull-up;
			};
		};

		uartdm_nfc_rx {
			qcom,pins = <&gp 5>;
			qcom,pin-func = <0>;
			qcom,num-grp-pins = <1>;
			label = "uartdm_nfc_rx";
			uartdm_nfc_rx_default: uartdm_nfc_rx_default {
				drive-strength = <2>;
				input-debounce = <0>;
				bias-pull-up;
			};
			uartdm_nfc_rx_active: uartdm_nfc_rx_active {
				drive-strength = <2>;
				input-debounce = <0>;
				bias-pull-up;
			};
			uartdm_nfc_rx_suspend: uartdm_nfc_rx_suspend {
				drive-strength = <2>;
				input-debounce = <0>;
				bias-pull-up;
			};
		};

		uartdm_nfc_rx_f2 {
			qcom,pins = <&gp 5>;
			qcom,pin-func  = <2>;
			qcom,num-grp-pins = <1>;
			label = "uartdm_nfc_rx_f2";
			uartdm_nfc_rx_f2_default: uartdm_nfc_rx_f2_default {
				drive-strength = <2>;
				input-debounce = <0>;
				bias-pull-up;
			};
			uartdm_nfc_rx_f2_active: uartdm_nfc_rx_f2_active {
				drive-strength = <2>;
				input-debounce = <0>;
				bias-pull-up;
			};
			uartdm_nfc_rx_f2_suspend: uartdm_nfc_rx_f2_suspend {
				drive-strength = <2>;
				input-debounce = <0>;
				bias-pull-up;
			};
		};

		vkey_on {
			qcom,pins = <&gp 8>;
			qcom,pin-func = <0>;
			qcom,num-grp-pins = <1>;
			label = "vkey_on";
			vkey_on_default: vkey_on_default {
				drive-strength = <2>;
				output-low;
				bias-disable;
			};
			vkey_on_active: vkey_on_active {
				drive-strength = <2>;
				output-low;
				bias-disable;
			};
			vkey_on_suspend: vkey_on_suspend {
				drive-strength = <2>;
				output-low;
				bias-disable;
			};
		};

		vtps_ldo_en {
			qcom,pins = <&gp 9>;
			qcom,pin-func = <0>;
			qcom,num-grp-pins = <1>;
			label = "vtps_ldo_en";
			vtps_ldo_en_default: vtps_ldo_en_default {
				drive-strength = <2>;
				output-high;
				bias-disable;
			};
			vtps_ldo_en_active: vtps_ldo_en_active {
				drive-strength = <2>;
				output-high;
				bias-disable;
			};
			vtps_ldo_en_suspend: vtps_ldo_en_suspend {
				drive-strength = <2>;
				output-low;
				bias-disable;
			};
		};

		fc_vfc_rst {
			qcom,pins = <&gp 12>;
			qcom,pin-func = <0>;
			qcom,num-grp-pins = <1>;
			label = "fc_vfc_rst";
			fc_vfc_rst_default: fc_vfc_rst_default {
				drive-strength = <4>;
				output-low;
				bias-disable;
			};
			fc_vfc_rst_active: fc_vfc_rst_active {
				drive-strength = <4>;
				output-low;
				bias-disable;
			};
			fc_vfc_rst_suspend: fc_vfc_rst_suspend {
				drive-strength = <4>;
				output-low;
				bias-disable;
			};
		};

		vh_on {
			qcom,pins = <&gp 13>;
			qcom,pin-func = <0>;
			qcom,num-grp-pins = <1>;
			label = "vh_on";
			vh_on_default: vh_on_default {
				drive-strength = <2>;
				output-low;
				bias-disable;
			};
			vh_on_active: vh_on_active {
				drive-strength = <2>;
				output-low;
				bias-disable;
			};
			vh_on_suspend: vh_on_suspend {
				drive-strength = <2>;
				output-low;
				bias-disable;
			};
		};

		uartdm_tx {
			qcom,pins = <&gp 20>;
			qcom,pin-func = <0>;
			qcom,num-grp-pins = <1>;
			label = "uartdm_tx";
			uartdm_tx_default: uartdm_tx_default {
				drive-strength = <2>;
				output-low;
				bias-disable;
			};
			uartdm_tx_active: uartdm_tx_active {
				drive-strength = <2>;
				output-low;
				bias-disable;
			};
			uartdm_tx_suspend: uartdm_tx_suspend {
				drive-strength = <2>;
				output-low;
				bias-pull-down;
			};
		};

		uartdm_ir_tx {
			qcom,pins = <&gp 20>;
			qcom,pin-func = <0>;
			qcom,num-grp-pins = <1>;
			label = "uartdm_ir_tx";
			uartdm_ir_tx_default: uartdm_ir_tx_default {
				drive-strength = <2>;
				output-low;
				bias-disable;
			};
			uartdm_ir_tx_active: uartdm_ir_tx_active {
				drive-strength = <2>;
				output-low;
				bias-disable;
			};
			uartdm_ir_tx_suspend: uartdm_ir_tx_suspend {
				drive-strength = <2>;
				output-low;
				bias-pull-down;
			};
		};

		uartdm_ir_tx_f3 {
			qcom,pins = <&gp 20>;
			qcom,pin-func = <3>;
			qcom,num-grp-pins = <1>;
			label = "uartdm_ir_tx_f3";
			uartdm_ir_tx_f3_default: uartdm_ir_tx_f3_default {
				drive-strength = <2>;
				output-low;
				bias-disable;
			};
			uartdm_ir_tx_f3_active: uartdm_ir_tx_f3_active {
				drive-strength = <2>;
				output-low;
				bias-disable;
			};
			uartdm_ir_tx_f3_suspend: uartdm_ir_tx_f3_suspend {
				drive-strength = <2>;
				output-low;
				bias-pull-down;
			};
		};

		uartdm_rx {
			qcom,pins = <&gp 21>;
			qcom,pin-func = <0>;
			qcom,num-grp-pins = <1>;
			label = "uartdm_rx";
			uartdm_rx_default: uartdm_rx_default {
				drive-strength = <2>;
				input-debounce = <0>;
				bias-disable;
			};
			uartdm_rx_active: uartdm_rx_active {
				drive-strength = <2>;
				input-debounce = <0>;
				bias-disable;
			};
			uartdm_rx_suspend: uartdm_rx_suspend {
				drive-strength = <2>;
				input-debounce = <0>;
				bias-disable;
			};
		};

		uartdm_rx_f3 {
			qcom,pins = <&gp 21>;
			qcom,pin-func = <3>;
			qcom,num-grp-pins = <1>;
			label = "uartdm_rx_f3";
			uartdm_rx_f3_active: uartdm_rx_f3_active {
				drive-strength = <2>;
				input-debounce = <0>;
				bias-disable;
			};
		};

		uartdm_ir_rx {
			qcom,pins = <&gp 21>;
			qcom,pin-func = <0>;
			qcom,num-grp-pins = <1>;
			label = "uartdm_ir_rx";
			uartdm_ir_rx_default: uartdm_ir_rx_default {
				drive-strength = <2>;
				input-debounce = <0>;
				bias-disable;
			};
			uartdm_ir_rx_active: uartdm_ir_rx_active {
				drive-strength = <2>;
				input-debounce = <0>;
				bias-disable;
			};
			uartdm_ir_rx_suspend: uartdm_ir_rx_suspend {
				drive-strength = <2>;
				input-debounce = <0>;
				bias-disable;
			};
		};

		uartdm_ir_rx_f3 {
			qcom,pins = <&gp 21>;
			qcom,pin-func = <3>;
			qcom,num-grp-pins = <1>;
			label = "uartdm_ir_rx_f3";
			uartdm_ir_rx_f3_default: uartdm_ir_rx_f3_default {
				drive-strength = <2>;
				input-debounce = <0>;
				bias-disable;
			};
			uartdm_ir_rx_f3_active: uartdm_ir_rx_f3_active {
				drive-strength = <2>;
				input-debounce = <0>;
				bias-disable;
			};
			uartdm_ir_rx_f3_suspend: uartdm_ir_rx_f3_suspend {
				drive-strength = <2>;
				input-debounce = <0>;
				bias-disable;
			};
		};

		ir_pwdown {
			qcom,pins = <&gp 22>;
			qcom,pin-func = <0>;
			qcom,num-grp-pins = <1>;
			label = "ir_pwdown";
			ir_pwdown_default: ir_pwdown_default {
				drive-strength = <2>;
				output-high;
				bias-disable;
			};
			ir_pwdown_active: ir_pwdown_active {
				drive-strength = <2>;
				output-high;
				bias-disable;
			};
			ir_pwdown_suspend: ir_pwdown_suspend {
				drive-strength = <2>;
				output-high;
				bias-pull-up;
			};
		};

		vcamd_ldo_en {
			qcom,pins = <&gp 23>;
			qcom,pin-func = <0>;
			qcom,num-grp-pins = <1>;
			label = "vcamd_ldo_en";
			vcamd_ldo_en_default: vcamd_ldo_en_default {
				drive-strength = <2>;
				output-low;
				bias-disable;
			};
			vcamd_ldo_en_active: vcamd_ldo_en_active {
				drive-strength = <2>;
				output-low;
				bias-disable;
			};
			vcamd_ldo_en_suspend: vcamd_ldo_en_suspend {
				drive-strength = <2>;
				output-low;
				bias-pull-down;
			};
		};

		tp_rst_n {
			qcom,pins = <&gp 24>;
			qcom,pin-func = <0>;
			qcom,num-grp-pins = <1>;
			label = "tp_rst_n";
			tp_rst_n_default: tp_rst_n_default {
				drive-strength = <2>;
				output-low;
				bias-disable;
			};
			tp_rst_n_active: tp_rst_n_active {
				drive-strength = <2>;
				output-low;
				bias-disable;
			};
			tp_rst_n_suspend: tp_rst_n_suspend {
				drive-strength = <2>;
				output-low;
				bias-disable;
			};
		};

		vbus_rst {
			qcom,pins = <&gp 27>;
			qcom,pin-func = <0>;
			qcom,num-grp-pins = <1>;
			label = "vbus_rst";
			vbus_rst_default: vbus_rst_default {
				drive-strength = <2>;
				output-low;
				bias-disable;
			};
			vbus_rst_active: vbus_rst_active {
				drive-strength = <2>;
				output-low;
				bias-disable;
			};
			vbus_rst_suspend: vbus_rst_suspend {
				drive-strength = <2>;
				output-low;
				bias-disable;
			};
		};

		cam_en_n {
			qcom,pins = <&gp 31>;
			qcom,pin-func = <0>;
			qcom,num-grp-pins = <1>;
			label = "cam_en_n";
			cam_en_n_default: cam_en_n_default {
				drive-strength = <2>;
				input-debounce = <0>;
				bias-pull-down;
			};
			cam_en_n_active: cam_en_n_active {
				drive-strength = <2>;
				input-debounce = <0>;
				bias-pull-down;
			};
			cam_en_n_suspend: cam_en_n_suspend {
				drive-strength = <2>;
				input-debounce = <0>;
				bias-pull-down;
			};
		};

		usb_therm_n {
			qcom,pins = <&gp 36>;
			qcom,pin-func = <0>;
			qcom,num-grp-pins = <1>;
			label = "usb_therm_n";
			usb_therm_n_default: usb_therm_n_default {
				drive-strength = <2>;
				input-debounce = <0>;
				bias-pull-up;
			};
			usb_therm_n_active: usb_therm_n_active {
				drive-strength = <2>;
				input-debounce = <0>;
				bias-pull-up;
			};
			usb_therm_n_suspend: usb_therm_n_suspend {
				drive-strength = <2>;
				input-debounce = <0>;
				bias-pull-up;
			};
		};

		micon_brmp {
			qcom,pins = <&gp 38>;
			qcom,pin-func = <0>;
			qcom,num-grp-pins = <1>;
			label = "micon_brmp";
			micon_brmp_default: micon_brmp_default {
				drive-strength = <4>;
				input-debounce = <0>;
				bias-pull-down;
			};
			micon_brmp_active: micon_brmp_active {
				drive-strength = <4>;
				output-low = <0>;
				bias-disable;
			};
			micon_brmp_suspend: micon_brmp_suspend {
				drive-strength = <4>;
				input-debounce = <0>;
				bias-pull-down;
			};
		};

		usb_int_n {
			qcom,pins = <&gp 49>;
			qcom,pin-func = <0>;
			qcom,num-grp-pins = <1>;
			label = "usb_int_n";
			usb_int_n_default: usb_int_n_default {
				drive-strength = <2>;
				input-debounce = <0>;
				bias-pull-up;
			};
			usb_int_n_active: usb_int_n_active {
				drive-strength = <2>;
				input-debounce = <0>;
				bias-pull-up;
			};
			usb_int_n_suspend: usb_int_n_suspend {
				drive-strength = <2>;
				input-debounce = <0>;
				bias-pull-up;
			};
		};

		m12mo_into {
			qcom,pins = <&gp 50>;
			qcom,pin-func = <0>;
			qcom,num-grp-pins = <1>;
			label = "m12mo_into";
			m12mo_into_default: m12mo_into_default {
				drive-strength = <2>;
				input-debounce = <0>;
				bias-pull-down;
			};
			m12mo_into_active: m12mo_into_active {
				drive-strength = <2>;
				input-debounce = <0>;
				bias-pull-down;
			};
			m12mo_into_suspend: m12mo_into_suspend {
				drive-strength = <2>;
				input-debounce = <0>;
				bias-pull-down;
			};
		};

		vsensor_18_on {
			qcom,pins = <&gp 51>;
			qcom,pin-func = <0>;
			qcom,num-grp-pins = <1>;
			label = "vsensor_18_on";
			vsensor_18_on_default: vsensor_18_on_default {
				drive-strength = <2>;
				output-low;
				bias-disable;
			};
			vsensor_18_on_active: vsensor_18_on_active {
				drive-strength = <2>;
				output-high;
				bias-disable;
			};
			vsensor_18_on_suspend: vsensor_18_on_suspend {
				drive-strength = <2>;
				output-high;
				bias-pull-up;
			};
		};

		usb_therm_op {
			qcom,pins = <&gp 52>;
			qcom,pin-func = <0>;
			qcom,num-grp-pins = <1>;
			label = "usb_therm_op";
			usb_therm_op_default: usb_therm_op_default {
				drive-strength = <2>;
				input-debounce = <0>;
				bias-pull-down;
			};
			usb_therm_op_active: usb_therm_op_active {
				drive-strength = <2>;
				input-debounce = <0>;
				bias-pull-down;
			};
			usb_therm_op_suspend: usb_therm_op_suspend {
				drive-strength = <2>;
				input-debounce = <0>;
				bias-pull-down;
			};
		};

		wdog_disable {
			qcom,pins = <&gp 76>;
			qcom,pin-func = <0>;
			qcom,num-grp-pins = <1>;
			label = "wdog_disable";
			wdog_disable_default: wdog_disable_default {
				drive-strength = <2>;
				input-debounce = <0>;
				bias-pull-down;
			};
			wdog_disable_active: wdog_disable_active {
				drive-strength = <2>;
				input-debounce = <0>;
				bias-pull-down;
			};
			wdog_disable_suspend: wdog_disable_suspend {
				drive-strength = <2>;
				input-debounce = <0>;
				bias-pull-down;
			};
		};

		hs_det {
			qcom,pins = <&gp 93>;
			qcom,pin-func = <0>;
			qcom,num-grp-pins = <1>;
			label = "hs_det";
			hs_det_default: hs_det_default {
				drive-strength = <2>;
				output-high;
				bias-disable;
			};
			hs_det_active: hs_det_active {
				drive-strength = <2>;
				output-high;
				bias-disable;
			};
			hs_det_suspend: hs_det_suspend {
				drive-strength = <2>;
				output-high;
				bias-disable;
			};
		};

		tp_int {
			qcom,pins = <&gp 97>;
			qcom,pin-func = <0>;
			qcom,num-grp-pins = <1>;
			label = "tp_int";
			tp_int_default: tp_int_default {
				drive-strength = <2>;
				input-debounce = <0>;
				bias-pull-down;
			};
			tp_int_active: tp_int_active {
				drive-strength = <2>;
				input-debounce = <0>;
				bias-pull-down;
			};
			tp_int_suspend: tp_int_suspend {
				drive-strength = <2>;
				input-debounce = <0>;
				bias-pull-down;
			};
		};

		usb_rst_n {
			qcom,pins = <&gp 99>;
			qcom,pin-func = <0>;
			qcom,num-grp-pins = <1>;
			label = "usb_rst_n";
			usb_rst_n_active: usb_rst_n_active {
				drive-strength = <2>;
				output-low;
				bias-disable;
			};
			usb_rst_n_suspend: usb_rst_n_suspend {
				drive-strength = <2>;
				output-high;
				bias-disable;
			};
		};

		carrier_sel {
			qcom,pins = <&gp 110>;
			qcom,pin-func = <0>;
			qcom,num-grp-pins = <1>;
			label = "carrier_sel";
			carrier_sel_default: carrier_sel_default {
				drive-strength = <2>;
				input-debounce = <0>;
				bias-pull-down;
			};
			carrier_sel_active: carrier_sel_active {
				drive-strength = <2>;
				input-debounce = <0>;
				bias-pull-down;
			};
			carrier_sel_suspend: carrier_sel_suspend {
				drive-strength = <2>;
				input-debounce = <0>;
				bias-pull-down;
			};
		};

		micon_rst_n {
			qcom,pins = <&gp 111>;
			qcom,pin-func = <0>;
			qcom,num-grp-pins = <1>;
			label = "micon_rst_n";
			micon_rst_n_default: micon_rst_n_default {
				drive-strength = <2>;
				output-low;
				bias-disable;
			};
			micon_rst_n_active: micon_rst_n_active {
				drive-strength = <2>;
				output-high;
				bias-disable;
			};
			micon_rst_n_suspend: micon_rst_n_suspend {
				drive-strength = <2>;
				output-high;
				bias-disable;
			};
		};

		micon_int_n {
			qcom,pins = <&gp 112>;
			qcom,pin-func = <0>;
			qcom,num-grp-pins = <1>;
			label = "micon_int_n";
			micon_int_n_default: micon_int_n_default {
				drive-strength = <2>;
				input-debounce = <0>;
				bias-pull-up;
			};
			micon_int_n_active: micon_int_n_active {
				drive-strength = <2>;
				input-debounce = <0>;
				bias-pull-up;
			};
			micon_int_n_suspend: micon_int_n_suspend {
				drive-strength = <2>;
				input-debounce = <0>;
				bias-pull-up;
			};
		};

	};
};
